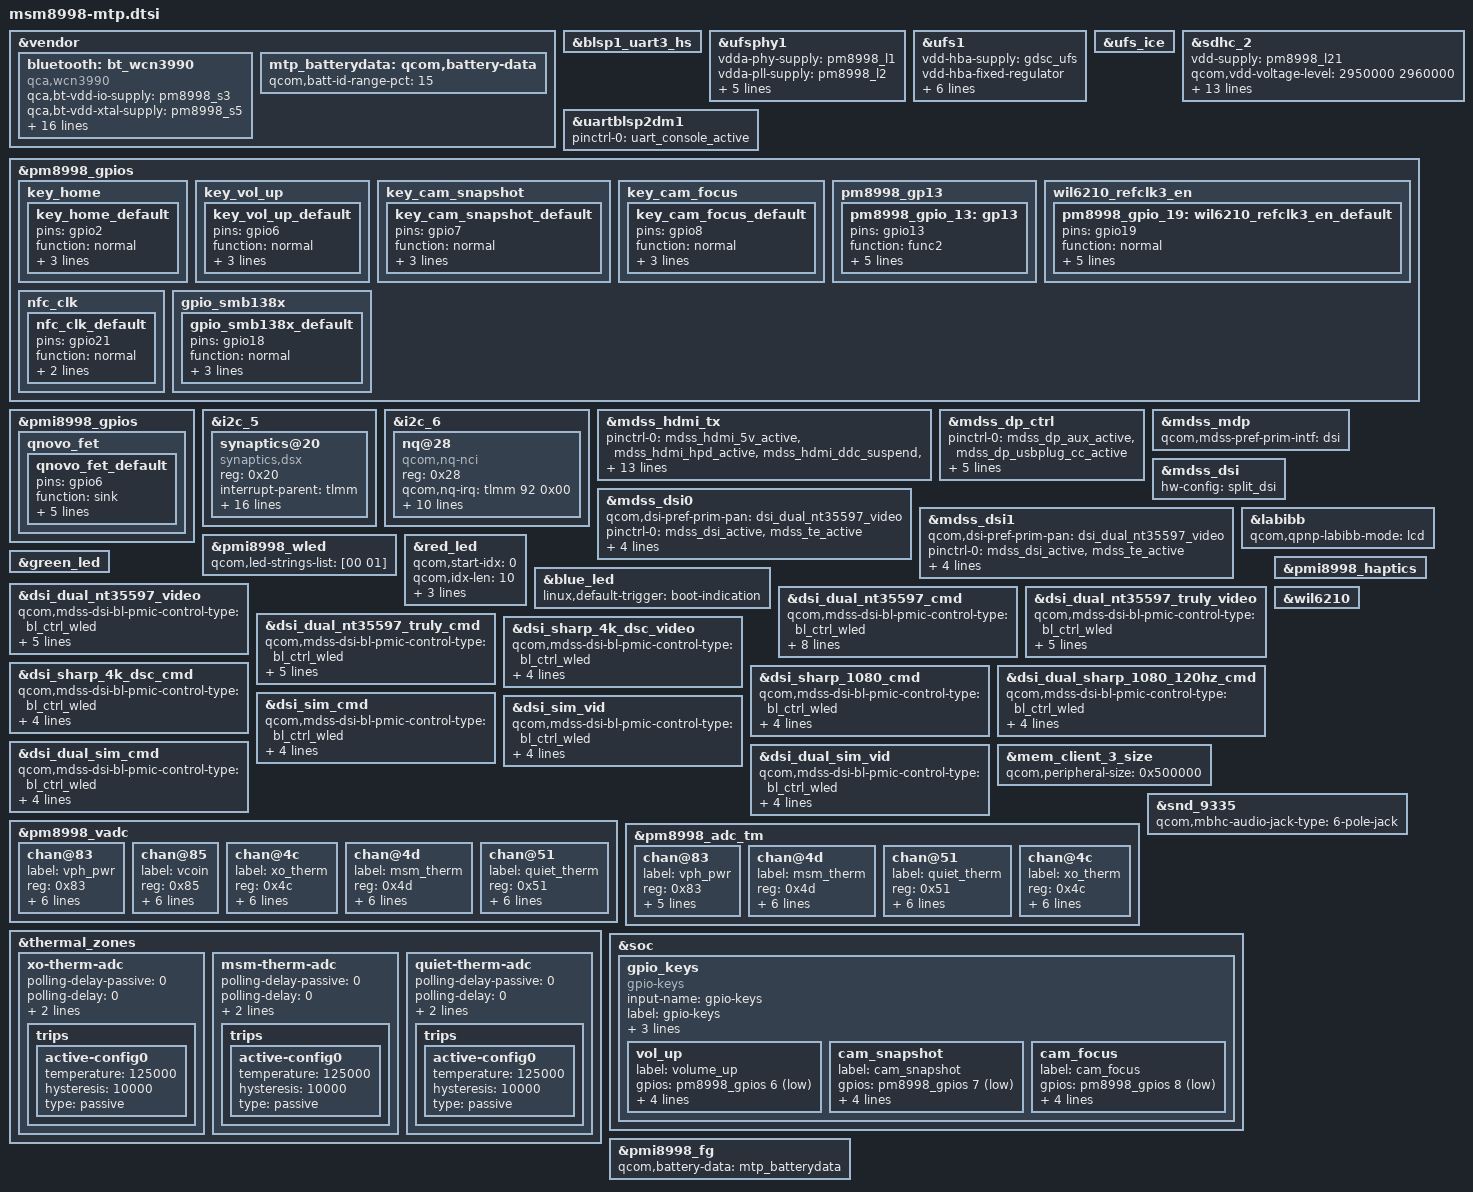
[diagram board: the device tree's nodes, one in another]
/* Copyright (c) 2016-2017, The Linux Foundation. All rights reserved.
 *
 * This program is free software; you can redistribute it and/or modify
 * it under the terms of the GNU General Public License version 2 and
 * only version 2 as published by the Free Software Foundation.
 *
 * This program is distributed in the hope that it will be useful,
 * but WITHOUT ANY WARRANTY; without even the implied warranty of
 * MERCHANTABILITY or FITNESS FOR A PARTICULAR PURPOSE.  See the
 * GNU General Public License for more details.
 */

#include <dt-bindings/interrupt-controller/irq.h>
#include <dt-bindings/pinctrl/qcom,pmic-gpio.h>
#include <dt-bindings/pinctrl/qcom,pmic-mpp.h>

#include "msm8998-camera-sensor-mtp.dtsi"

&vendor {
	bluetooth: bt_wcn3990 {
		compatible = "qca,wcn3990";
		qca,bt-vdd-io-supply = <&pm8998_s3>;
		qca,bt-vdd-xtal-supply = <&pm8998_s5>;
		qca,bt-vdd-core-supply = <&pm8998_l7>;
		qca,bt-vdd-pa-supply = <&pm8998_l17>;
		qca,bt-vdd-ldo-supply = <&pm8998_l25>;
		qca,bt-chip-pwd-supply = <&pmi8998_bob_pin1>;
		clocks = <&clock_rpmcc RPM_SMD_RF_CLK2_PIN>;
		clock-names = "rf_clk2";

		qca,bt-vdd-io-voltage-level = <1352000 1352000>;
		qca,bt-vdd-xtal-voltage-level = <2040000 2040000>;
		qca,bt-vdd-core-voltage-level = <1800000 1800000>;
		qca,bt-vdd-pa-voltage-level = <1304000 1304000>;
		qca,bt-vdd-ldo-voltage-level = <3312000 3312000>;
		qca,bt-chip-pwd-voltage-level = <3600000 3600000>;

		qca,bt-vdd-io-current-level = <1>; /* LPM/PFM */
		qca,bt-vdd-xtal-current-level = <1>; /* LPM/PFM */
		qca,bt-vdd-core-current-level = <1>; /* LPM/PFM */
		qca,bt-vdd-pa-current-level = <1>; /* LPM/PFM */
		qca,bt-vdd-ldo-current-level = <1>; /* LPM/PFM */
	};
};

&blsp1_uart3_hs {
	status = "ok";
};

&ufsphy1 {
	vdda-phy-supply = <&pm8998_l1>;
	vdda-pll-supply = <&pm8998_l2>;
	vddp-ref-clk-supply = <&pm8998_l26>;
	vdda-phy-max-microamp = <51400>;
	vdda-pll-max-microamp = <14600>;
	vddp-ref-clk-max-microamp = <100>;
	vddp-ref-clk-always-on;
	status = "ok";
};

&ufs1 {
	vdd-hba-supply = <&gdsc_ufs>;
	vdd-hba-fixed-regulator;
	vcc-supply = <&pm8998_l20>;
	vccq-supply = <&pm8998_l26>;
	vccq2-supply = <&pm8998_s4>;
	vcc-max-microamp = <750000>;
	vccq-max-microamp = <560000>;
	vccq2-max-microamp = <750000>;
	status = "ok";
};

&ufs_ice {
	status = "ok";
};

&sdhc_2 {
	vdd-supply = <&pm8998_l21>;
	qcom,vdd-voltage-level = <2950000 2960000>;
	qcom,vdd-current-level = <200 800000>;

	vdd-io-supply = <&pm8998_l13>;
	qcom,vdd-io-voltage-level = <1808000 2960000>;
	qcom,vdd-io-current-level = <200 22000>;

	pinctrl-names = "active", "sleep";
	pinctrl-0 = <&sdc2_clk_on  &sdc2_cmd_on &sdc2_data_on &sdc2_cd_on>;
	pinctrl-1 = <&sdc2_clk_off &sdc2_cmd_off &sdc2_data_off &sdc2_cd_off>;

	qcom,clk-rates = <400000 20000000 25000000
				50000000 100000000 200000000>;
	qcom,bus-speed-mode = "SDR12", "SDR25", "SDR50", "DDR50", "SDR104";

	cd-gpios = <&tlmm 95 0x1>;

	status = "ok";
};

&uartblsp2dm1 {
	status = "ok";
	pinctrl-names = "default";
	pinctrl-0 = <&uart_console_active>;
};

&pm8998_gpios {
	/* GPIO 2 for Home Key */
	key_home {
		key_home_default: key_home_default {
			pins = "gpio2";
			function = "normal";
			input-enable;
			bias-pull-up;
			power-source = <0>;
		};
	};

	/* GPIO 6 for Vol+ Key */
	key_vol_up {
		key_vol_up_default: key_vol_up_default {
			pins = "gpio6";
			function = "normal";
			input-enable;
			bias-pull-up;
			power-source = <0>;
		};
	};

	/* GPIO 7 for Snapshot Key */
	key_cam_snapshot {
		key_cam_snapshot_default: key_cam_snapshot_default {
			pins = "gpio7";
			function = "normal";
			input-enable;
			bias-pull-up;
			power-source = <0>;
		};
	};

	/* GPIO 8 for Focus Key */
	key_cam_focus {
		key_cam_focus_default: key_cam_focus_default {
			pins = "gpio8";
			function = "normal";
			input-enable;
			bias-pull-up;
			power-source = <0>;
		};
	};

	pm8998_gp13 {
		pm8998_gpio_13: gp13 {
			pins = "gpio13";
			function = "func2";
			output-low;
			drive-push-pull;
			bias-disable;
			qcom,drive-strength = <PMIC_GPIO_STRENGTH_HIGH>;
			power-source = <0>;
		};
	};

	/* GPIO 19 - wil6210 refclk3_en */
	wil6210_refclk3_en {
		pm8998_gpio_19: wil6210_refclk3_en_default {
			pins = "gpio19";
			function = "normal";
			output-low;
			drive-push-pull;
			bias-disable;
			qcom,drive-strength = <PMIC_GPIO_STRENGTH_HIGH>;
			power-source = <1>; /* VIN1 GPIO_MV */
		};
	};

	/* GPIO 21 (NFC_CLK_REQ) */
	nfc_clk {
		nfc_clk_default: nfc_clk_default {
			pins = "gpio21";
			function = "normal";
			input-enable;
			power-source = <1>;
		};
	};

	/* GPIO 18 SMB138X */
	gpio_smb138x {
		gpio_smb138x_default: gpio_smb138x_default {
			pins = "gpio18";
			function = "normal";
			input-enable;
			bias-pull-up;
			power-source = <0>;
		};
	};
};

&pmi8998_gpios {
	/* GPIO 6 for the internal QNOVO discharge FET control signal */
	qnovo_fet {
		qnovo_fet_default: qnovo_fet_default {
			pins = "gpio6";
			function = "sink";
			output-low;
			drive-push-pull;
			bias-disable;
			qcom,drive-strength = <PMIC_GPIO_STRENGTH_HIGH>;
			power-source = <0>;
		};
	};
};

&i2c_5 {
	status = "okay";
	synaptics@20 {
		compatible = "synaptics,dsx";
		reg = <0x20>;
		interrupt-parent = <&tlmm>;
		interrupts = <125 0x2008>;
		vdd-supply = <&pm8998_l6>;
		avdd-supply = <&pm8998_l28>;
		synaptics,vdd-voltage = <1808000 1808000>;
		synaptics,avdd-voltage = <3008000 3008000>;
		synaptics,vdd-current = <40000>;
		synaptics,avdd-current = <20000>;
		pinctrl-names = "pmx_ts_active", "pmx_ts_suspend";
		pinctrl-0 = <&ts_active>;
		pinctrl-1 = <&ts_int_suspend &ts_reset_suspend>;
		synaptics,display-coords = <0 0 1439 2559>;
		synaptics,panel-coords = <0 0 1439 2559>;
		synaptics,reset-gpio = <&tlmm 89 0x00>;
		synaptics,irq-gpio = <&tlmm 125 0x2008>;
		synaptics,disable-gpios;
		synaptics,fw-name = "PR1702898-s3528t_60QHD_00400001.img";
	};
};

&i2c_6 { /* BLSP1 QUP6 (NFC) */
	status = "okay";
	nq@28 {
		compatible = "qcom,nq-nci";
		reg = <0x28>;
		qcom,nq-irq = <&tlmm 92 0x00>;
		qcom,nq-ven = <&tlmm 12 0x00>;
		qcom,nq-firm = <&tlmm 93 0x00>;
		qcom,nq-clkreq = <&pm8998_gpios 21 0x00>;
		qcom,nq-esepwr = <&tlmm 116 0x00>;
		interrupt-parent = <&tlmm>;
		qcom,clk-src = "BBCLK3";
		interrupts = <92 0>;
		interrupt-names = "nfc_irq";
		pinctrl-names = "nfc_active", "nfc_suspend";
		pinctrl-0 = <&nfc_int_active &nfc_enable_active>;
		pinctrl-1 = <&nfc_int_suspend &nfc_enable_suspend>;
		clocks = <&clock_rpmcc RPM_SMD_LN_BB_CLK3_PIN>;
		clock-names = "ref_clk";
	};
};

&mdss_hdmi_tx {
	pinctrl-names = "hdmi_hpd_active", "hdmi_ddc_active", "hdmi_cec_active",
				"hdmi_active", "hdmi_sleep";
	pinctrl-0 = <&mdss_hdmi_5v_active  &mdss_hdmi_hpd_active
			&mdss_hdmi_ddc_suspend &mdss_hdmi_cec_suspend>;
	pinctrl-1 = <&mdss_hdmi_5v_active &mdss_hdmi_hpd_active
			&mdss_hdmi_ddc_active &mdss_hdmi_cec_suspend>;
	pinctrl-2 = <&mdss_hdmi_5v_active &mdss_hdmi_hpd_active
			&mdss_hdmi_cec_active &mdss_hdmi_ddc_suspend>;
	pinctrl-3 = <&mdss_hdmi_5v_active &mdss_hdmi_hpd_active
			&mdss_hdmi_ddc_active &mdss_hdmi_cec_active>;
	pinctrl-4 = <&mdss_hdmi_5v_suspend &mdss_hdmi_hpd_suspend
			&mdss_hdmi_ddc_suspend &mdss_hdmi_cec_suspend>;
};

&mdss_dp_ctrl {
	pinctrl-names = "mdss_dp_active", "mdss_dp_sleep";
	pinctrl-0 = <&mdss_dp_aux_active &mdss_dp_usbplug_cc_active>;
	pinctrl-1 = <&mdss_dp_aux_suspend &mdss_dp_usbplug_cc_suspend>;
	qcom,aux-en-gpio = <&tlmm 77 0>;
	qcom,aux-sel-gpio = <&tlmm 78 0>;
	qcom,usbplug-cc-gpio = <&tlmm 38 0>;
};

&mdss_mdp {
	qcom,mdss-pref-prim-intf = "dsi";
};

&mdss_dsi {
	hw-config = "split_dsi";
};

&mdss_dsi0 {
	qcom,dsi-pref-prim-pan = <&dsi_dual_nt35597_video>;
	pinctrl-names = "mdss_default", "mdss_sleep";
	pinctrl-0 = <&mdss_dsi_active &mdss_te_active>;
	pinctrl-1 = <&mdss_dsi_suspend &mdss_te_suspend>;
	qcom,platform-reset-gpio = <&tlmm 94 0>;
	qcom,platform-te-gpio = <&tlmm 10 0>;
	qcom,panel-mode-gpio = <&tlmm 91 0>;
};

&mdss_dsi1 {
	qcom,dsi-pref-prim-pan = <&dsi_dual_nt35597_video>;
	pinctrl-names = "mdss_default", "mdss_sleep";
	pinctrl-0 = <&mdss_dsi_active &mdss_te_active>;
	pinctrl-1 = <&mdss_dsi_suspend &mdss_te_suspend>;
	qcom,platform-reset-gpio = <&tlmm 94 0>;
	qcom,platform-te-gpio = <&tlmm 10 0>;
	qcom,panel-mode-gpio = <&tlmm 91 0>;
};

&labibb {
	status = "ok";
	qcom,qpnp-labibb-mode = "lcd";
};

&pmi8998_wled {
	status = "ok";
	qcom,led-strings-list = [00 01];
};

&red_led {
	/delete-property/ linux,default-trigger;
	qcom,start-idx = <0>;
	qcom,idx-len = <10>;
	qcom,duty-pcts = [00 19 32 4b 64
			64 4b 32 19 00];
	qcom,use-blink;
};

&green_led {
	/delete-property/ linux,default-trigger;
};

&blue_led {
	linux,default-trigger = "boot-indication";
};

&dsi_dual_nt35597_video {
	qcom,mdss-dsi-bl-pmic-control-type = "bl_ctrl_wled";
	qcom,mdss-dsi-bl-min-level = <1>;
	qcom,mdss-dsi-bl-max-level = <4095>;
	qcom,mdss-dsi-mode-sel-gpio-state = "dual_port";
	qcom,panel-supply-entries = <&dsi_panel_pwr_supply>;
};

&dsi_dual_nt35597_cmd {
	qcom,mdss-dsi-bl-pmic-control-type = "bl_ctrl_wled";
	qcom,mdss-dsi-bl-min-level = <1>;
	qcom,mdss-dsi-bl-max-level = <4095>;
	qcom,mdss-dsi-mode-sel-gpio-state = "dual_port";
	qcom,panel-supply-entries = <&dsi_panel_pwr_supply>;
	qcom,partial-update-enabled = "single_roi";
	qcom,panel-roi-alignment = <720 256 720 256 1440 256>;
};

&dsi_dual_nt35597_truly_video {
	qcom,mdss-dsi-bl-pmic-control-type = "bl_ctrl_wled";
	qcom,mdss-dsi-bl-min-level = <1>;
	qcom,mdss-dsi-bl-max-level = <4095>;
	qcom,mdss-dsi-mode-sel-gpio-state = "dual_port";
	qcom,panel-supply-entries = <&dsi_panel_pwr_supply>;
};

&dsi_dual_nt35597_truly_cmd {
	qcom,mdss-dsi-bl-pmic-control-type = "bl_ctrl_wled";
	qcom,mdss-dsi-bl-min-level = <1>;
	qcom,mdss-dsi-bl-max-level = <4095>;
	qcom,mdss-dsi-mode-sel-gpio-state = "dual_port";
	qcom,panel-supply-entries = <&dsi_panel_pwr_supply>;
};

&dsi_sharp_4k_dsc_video {
	qcom,mdss-dsi-bl-pmic-control-type = "bl_ctrl_wled";
	qcom,mdss-dsi-bl-min-level = <1>;
	qcom,mdss-dsi-bl-max-level = <4095>;
	qcom,panel-supply-entries = <&dsi_panel_pwr_supply>;
};

&dsi_sharp_4k_dsc_cmd {
	qcom,mdss-dsi-bl-pmic-control-type = "bl_ctrl_wled";
	qcom,mdss-dsi-bl-min-level = <1>;
	qcom,mdss-dsi-bl-max-level = <4095>;
	qcom,panel-supply-entries = <&dsi_panel_pwr_supply>;
};

&dsi_sharp_1080_cmd {
	qcom,mdss-dsi-bl-pmic-control-type = "bl_ctrl_wled";
	qcom,mdss-dsi-bl-min-level = <1>;
	qcom,mdss-dsi-bl-max-level = <4095>;
	qcom,panel-supply-entries = <&dsi_panel_pwr_supply>;
};

&dsi_dual_sharp_1080_120hz_cmd {
	qcom,mdss-dsi-bl-pmic-control-type = "bl_ctrl_wled";
	qcom,mdss-dsi-bl-min-level = <1>;
	qcom,mdss-dsi-bl-max-level = <4095>;
	qcom,panel-supply-entries = <&dsi_panel_pwr_supply>;
};

&dsi_sim_cmd {
	qcom,mdss-dsi-bl-pmic-control-type = "bl_ctrl_wled";
	qcom,mdss-dsi-bl-min-level = <1>;
	qcom,mdss-dsi-bl-max-level = <4095>;
	qcom,panel-supply-entries = <&dsi_panel_pwr_supply>;
};

&dsi_sim_vid {
	qcom,mdss-dsi-bl-pmic-control-type = "bl_ctrl_wled";
	qcom,mdss-dsi-bl-min-level = <1>;
	qcom,mdss-dsi-bl-max-level = <4095>;
	qcom,panel-supply-entries = <&dsi_panel_pwr_supply>;
};

&dsi_dual_sim_cmd {
	qcom,mdss-dsi-bl-pmic-control-type = "bl_ctrl_wled";
	qcom,mdss-dsi-bl-min-level = <1>;
	qcom,mdss-dsi-bl-max-level = <4095>;
	qcom,panel-supply-entries = <&dsi_panel_pwr_supply>;
};

&dsi_dual_sim_vid {
	qcom,mdss-dsi-bl-pmic-control-type = "bl_ctrl_wled";
	qcom,mdss-dsi-bl-min-level = <1>;
	qcom,mdss-dsi-bl-max-level = <4095>;
	qcom,panel-supply-entries = <&dsi_panel_pwr_supply>;
};

&mem_client_3_size {
	qcom,peripheral-size = <0x500000>;
};

&pmi8998_haptics {
	status = "okay";
};

&pm8998_vadc {
	chan@83 {
		label = "vph_pwr";
		reg = <0x83>;
		qcom,decimation = <2>;
		qcom,pre-div-channel-scaling = <1>;
		qcom,calibration-type = "absolute";
		qcom,scale-function = <0>;
		qcom,hw-settle-time = <0>;
		qcom,fast-avg-setup = <0>;
	};

	chan@85 {
		label = "vcoin";
		reg = <0x85>;
		qcom,decimation = <2>;
		qcom,pre-div-channel-scaling = <1>;
		qcom,calibration-type = "absolute";
		qcom,scale-function = <0>;
		qcom,hw-settle-time = <0>;
		qcom,fast-avg-setup = <0>;
	};

	chan@4c {
		label = "xo_therm";
		reg = <0x4c>;
		qcom,decimation = <2>;
		qcom,pre-div-channel-scaling = <0>;
		qcom,calibration-type = "ratiometric";
		qcom,scale-function = <4>;
		qcom,hw-settle-time = <2>;
		qcom,fast-avg-setup = <0>;
	};

	chan@4d {
		label = "msm_therm";
		reg = <0x4d>;
		qcom,decimation = <2>;
		qcom,pre-div-channel-scaling = <0>;
		qcom,calibration-type = "ratiometric";
		qcom,scale-function = <2>;
		qcom,hw-settle-time = <2>;
		qcom,fast-avg-setup = <0>;
	};

	chan@51 {
		label = "quiet_therm";
		reg = <0x51>;
		qcom,decimation = <2>;
		qcom,pre-div-channel-scaling = <0>;
		qcom,calibration-type = "ratiometric";
		qcom,scale-function = <2>;
		qcom,hw-settle-time = <2>;
		qcom,fast-avg-setup = <0>;
	};
};

&pm8998_adc_tm {
	chan@83 {
		label = "vph_pwr";
		reg = <0x83>;
		qcom,pre-div-channel-scaling = <1>;
		qcom,calibration-type = "absolute";
		qcom,scale-function = <0>;
		qcom,hw-settle-time = <0>;
		qcom,btm-channel-number = <0x60>;
	};

	chan@4d {
		label = "msm_therm";
		reg = <0x4d>;
		qcom,pre-div-channel-scaling = <0>;
		qcom,calibration-type = "ratiometric";
		qcom,scale-function = <2>;
		qcom,hw-settle-time = <2>;
		qcom,btm-channel-number = <0x68>;
		qcom,thermal-node;
	};

	chan@51 {
		label = "quiet_therm";
		reg = <0x51>;
		qcom,pre-div-channel-scaling = <0>;
		qcom,calibration-type = "ratiometric";
		qcom,scale-function = <2>;
		qcom,hw-settle-time = <2>;
		qcom,btm-channel-number = <0x70>;
		qcom,thermal-node;
	};

	chan@4c {
		label = "xo_therm";
		reg = <0x4c>;
		qcom,pre-div-channel-scaling = <0>;
		qcom,calibration-type = "ratiometric";
		qcom,scale-function = <4>;
		qcom,hw-settle-time = <2>;
		qcom,btm-channel-number = <0x78>;
		qcom,thermal-node;
	};
};

&thermal_zones {
	xo-therm-adc {
		polling-delay-passive = <0>;
		polling-delay = <0>;
		thermal-sensors = <&pm8998_adc_tm 0x4c>;
		thermal-governor = "user_space";

		trips {
			active-config0 {
				temperature = <125000>;
				hysteresis = <10000>;
				type = "passive";
			};
		};
	};

	msm-therm-adc {
		polling-delay-passive = <0>;
		polling-delay = <0>;
		thermal-sensors = <&pm8998_adc_tm 0x4d>;
		thermal-governor = "user_space";

		trips {
			active-config0 {
				temperature = <125000>;
				hysteresis = <10000>;
				type = "passive";
			};
		};
	};

	quiet-therm-adc {
		polling-delay-passive = <0>;
		polling-delay = <0>;
		thermal-sensors = <&pm8998_adc_tm 0x51>;
		thermal-governor = "user_space";

		trips {
			active-config0 {
				temperature = <125000>;
				hysteresis = <10000>;
				type = "passive";
			};
		};
	};
};

&wil6210 {
	status = "ok";
};

&snd_9335 {
	qcom,mbhc-audio-jack-type = "6-pole-jack";
};

&soc {
	gpio_keys {
		compatible = "gpio-keys";
		input-name = "gpio-keys";
		label = "gpio-keys";
		status = "okay";

		pinctrl-names = "default";
		pinctrl-0 = <&key_vol_up_default
			     &key_cam_snapshot_default
			     &key_cam_focus_default>;


		vol_up {
			label = "volume_up";
			gpios = <&pm8998_gpios 6 0x1>;
			linux,input-type = <1>;
			linux,code = <115>;
			gpio-key,wakeup;
			debounce-interval = <15>;
		};

		cam_snapshot {
			label = "cam_snapshot";
			gpios = <&pm8998_gpios 7 0x1>;
			linux,input-type = <1>;
			linux,code = <766>;
			gpio-key,wakeup;
			debounce-interval = <15>;
		};

		cam_focus {
			label = "cam_focus";
			gpios = <&pm8998_gpios 8 0x1>;
			linux,input-type = <1>;
			linux,code = <528>;
			gpio-key,wakeup;
			debounce-interval = <15>;
		};
	};
};

&vendor {
	mtp_batterydata: qcom,battery-data {
		qcom,batt-id-range-pct = <15>;
	};
};

&pmi8998_fg {
	qcom,battery-data = <&mtp_batterydata>;
};
